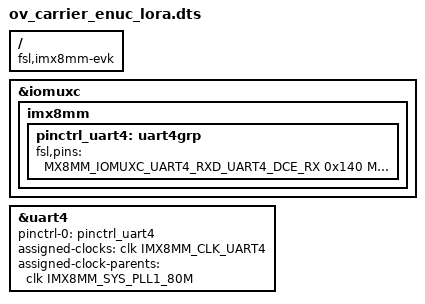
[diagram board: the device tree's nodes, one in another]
/**
 * Portenta-X8 dtb overlay file
 * Arduino 2021
 * Enable LORA modem serial port on Arduino Max carrier board
 * no RTS CTS only TX RX.
 * Gpios:
 * - Reset pin active low, ext. pull up of 1M on carrier
 *   (stm32h7 PF4, 163 in /sys/class/gpio/export)
 *
 * Example script to reset the modem:
 *
 * #!/bin/sh
 * echo 163 > /sys/class/gpio/export
 * echo out > /sys/class/gpio/gpio163/direction
 * echo 0 > /sys/class/gpio/gpio163/value
 * sleep 1
 * echo 1 > /sys/class/gpio/gpio163/value
 */

/dts-v1/;
/plugin/;

#include <dt-bindings/clock/imx8mm-clock.h>
#include "imx8mm-pinfunc.h"

/ {
	compatible = "fsl,imx8mm-evk", "fsl,imx8mm";

	fragment@0 {
		target = <&iomuxc>;
		__overlay__ {
			imx8mm {
				pinctrl_uart4: uart4grp {
					fsl,pins = <
						MX8MM_IOMUXC_UART4_RXD_UART4_DCE_RX			0x140
						MX8MM_IOMUXC_UART4_TXD_UART4_DCE_TX			0x140
					>;
				};
			};
		};
	};

	fragment@1 {
		target = <&uart4>;
		__overlay__ {
			pinctrl-names = "default";
			pinctrl-0 = <&pinctrl_uart4>;
			assigned-clocks = <&clk IMX8MM_CLK_UART4>;
			assigned-clock-parents = <&clk IMX8MM_SYS_PLL1_80M>;
			status = "okay";
		};
	};
};
